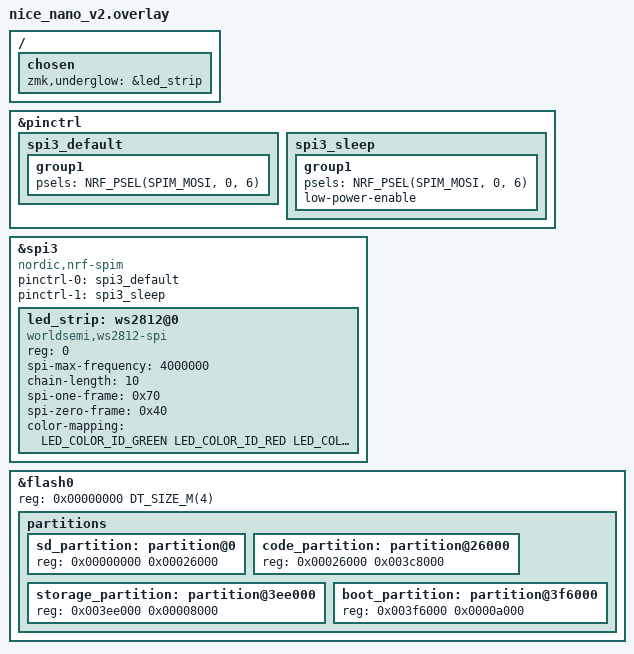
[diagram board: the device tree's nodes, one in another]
#include <dt-bindings/led/led.h>

&pinctrl {
    spi3_default: spi3_default {
        group1 {
            psels = <NRF_PSEL(SPIM_MOSI, 0, 6)>;
        };
    };

    spi3_sleep: spi3_sleep {
        group1 {
            psels = <NRF_PSEL(SPIM_MOSI, 0, 6)>;
            low-power-enable;
        };
    };
};

&spi3 {
    compatible = "nordic,nrf-spim";
    status = "okay";

    pinctrl-0 = <&spi3_default>;
    pinctrl-1 = <&spi3_sleep>;
    pinctrl-names = "default", "sleep";

    led_strip: ws2812@0 {
        compatible = "worldsemi,ws2812-spi";

        /* SPI */
        reg = <0>; /* ignored, but necessary for SPI bindings */
        spi-max-frequency = <4000000>;

        /* WS2812 */
        chain-length = <10>; /* arbitrary; change at will */
        spi-one-frame = <0x70>;
        spi-zero-frame = <0x40>;

        color-mapping = <LED_COLOR_ID_GREEN LED_COLOR_ID_RED LED_COLOR_ID_BLUE>;
    };
};

/ {
    chosen {
        zmk,underglow = &led_strip;
    };
};

/* Override flash size for build testing — actual hardware may differ */
&flash0 {
    reg = <0x00000000 DT_SIZE_M(4)>;

    partitions {
        /delete-node/ partition@0;
        /delete-node/ partition@26000;
        /delete-node/ partition@ec000;
        /delete-node/ partition@f4000;

        sd_partition: partition@0 {
            reg = <0x00000000 0x00026000>;
        };

        code_partition: partition@26000 {
            reg = <0x00026000 0x003c8000>;
        };

        storage_partition: partition@3ee000 {
            reg = <0x003ee000 0x00008000>;
        };

        boot_partition: partition@3f6000 {
            reg = <0x003f6000 0x0000a000>;
        };
    };
};
// vim: filetype=dts fdm=marker:
